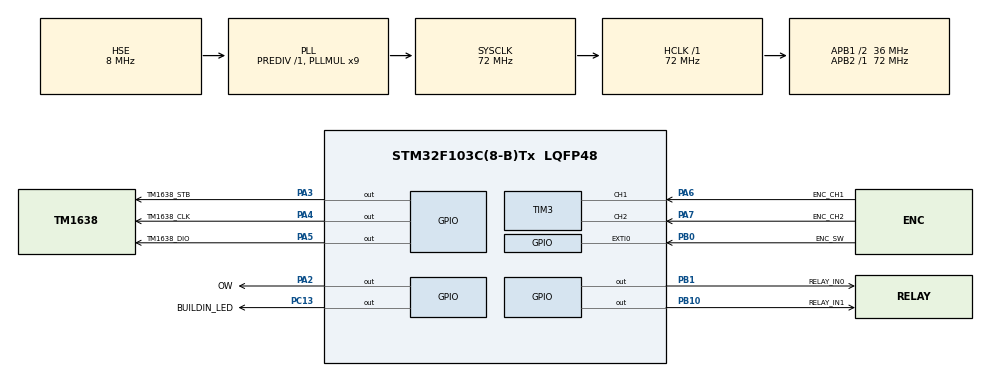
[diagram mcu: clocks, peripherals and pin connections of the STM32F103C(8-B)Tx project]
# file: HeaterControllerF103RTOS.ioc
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FREERTOS.Tasks01=runtime,24,512,start_runtime,Default,NULL,Dynamic,NULL,NULL
FREERTOS.configUSE_NEWLIB_REENTRANT=1
IWDG.Prescaler=IWDG_PRESCALER_256
Mcu.Family=STM32F1
Mcu.Name=STM32F103C(8-B)Tx
Mcu.Package=LQFP48
NVIC.EXTI0_IRQn=true\:5\:0\:false\:false\:true\:true\:true\:true\:true
NVIC.PriorityGroup=NVIC_PRIORITYGROUP_4
NVIC.TIM4_IRQn=true\:15\:0\:false\:false\:true\:false\:false\:true\:true
NVIC.TimeBase=TIM4_IRQn
NVIC.TimeBaseIP=TIM4
PA13.Mode=Serial_Wire
PA13.Signal=SYS_JTMS-SWDIO
PA14.Mode=Serial_Wire
PA14.Signal=SYS_JTCK-SWCLK
PA2.GPIO_Label=OW
PA2.GPIO_ModeDefaultOutputPP=GPIO_MODE_OUTPUT_OD
PA2.GPIO_PuPd=GPIO_NOPULL
PA2.PinState=GPIO_PIN_SET
PA2.Signal=GPIO_Output
PA3.GPIO_Label=TM1638_STB
PA3.Signal=GPIO_Output
PA4.GPIO_Label=TM1638_CLK
PA4.Signal=GPIO_Output
PA5.GPIO_Label=TM1638_DIO
PA5.Signal=GPIO_Output
PA6.GPIO_Label=ENC_CH1
PA6.GPIO_Mode=GPIO_MODE_INPUT
PA6.Signal=S_TIM3_CH1
PA7.GPIO_Label=ENC_CH2
PA7.Signal=S_TIM3_CH2
PB0.GPIO_Label=ENC_SW
PB0.GPIO_ModeDefaultEXTI=GPIO_MODE_IT_FALLING
PB0.GPIO_PuPd=GPIO_PULLUP
PB0.Signal=GPXTI0
PB1.GPIO_Label=RELAY_IN0
PB1.GPIO_ModeDefaultOutputPP=GPIO_MODE_OUTPUT_PP
PB1.GPIO_PuPd=GPIO_NOPULL
PB1.Signal=GPIO_Output
PB10.GPIO_Label=RELAY_IN1
PB10.GPIO_ModeDefaultOutputPP=GPIO_MODE_OUTPUT_PP
PB10.Signal=GPIO_Output
PC13-TAMPER-RTC.GPIO_Label=BUILDIN_LED
PC13-TAMPER-RTC.Signal=GPIO_Output
PD0-OSC_IN.Mode=HSE-External-Oscillator
PD0-OSC_IN.Signal=RCC_OSC_IN
PD1-OSC_OUT.Mode=HSE-External-Oscillator
PD1-OSC_OUT.Signal=RCC_OSC_OUT
ProjectManager.HeapSize=0x400
ProjectManager.StackSize=0x800
ProjectManager.TargetToolchain=STM32CubeIDE
RCC.AHBFreq_Value=72000000
RCC.APB1CLKDivider=RCC_HCLK_DIV2
RCC.APB1Freq_Value=36000000
RCC.APB1TimFreq_Value=72000000
RCC.APB2Freq_Value=72000000
RCC.APB2TimFreq_Value=72000000
RCC.HCLKFreq_Value=72000000
RCC.PLLMUL=RCC_PLL_MUL9
RCC.PLLSourceVirtual=RCC_PLLSOURCE_HSE
RCC.SYSCLKFreq_VALUE=72000000
RCC.SYSCLKSource=RCC_SYSCLKSOURCE_PLLCLK
RCC.USBFreq_Value=72000000
SH.S_TIM3_CH1.0=TIM3_CH1,Encoder_Interface
SH.S_TIM3_CH2.0=TIM3_CH2,Encoder_Interface
TIM1.Period=0xffff-1
TIM1.Prescaler=72-1
TIM3.EncoderMode=TIM_ENCODERMODE_TI12
TIM3.IC1Filter=10
VP_FREERTOS_VS_CMSIS_V2.Mode=CMSIS_V2
VP_IWDG_VS_IWDG.Mode=IWDG_Activate
VP_SYS_VS_tim4.Mode=TIM4
VP_TIM1_VS_ClockSourceINT.Mode=Internal
board=custom

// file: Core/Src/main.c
/* USER CODE BEGIN Header */
/**
  ******************************************************************************
  * @file           : main.c
  * @brief          : Main program body
  ******************************************************************************
  * @attention
  *
  * Copyright (c) 2024 STMicroelectronics.
  * All rights reserved.
  *
  * This software is licensed under terms that can be found in the LICENSE file
  * in the root directory of this software component.
  * If no LICENSE file comes with this software, it is provided AS-IS.
  *
  ******************************************************************************
  */
/* USER CODE END Header */
#include "main.h"
#include "cmsis_os.h"

/* USER CODE BEGIN Includes */
#include "controller.h"
#include "controller_devices.h"

/* USER CODE END Includes */

IWDG_HandleTypeDef hiwdg;

TIM_HandleTypeDef htim1;
TIM_HandleTypeDef htim3;

/* Definitions for runtime */
osThreadId_t runtimeHandle;
const osThreadAttr_t runtime_attributes = {
  .name = "runtime",
  .stack_size = 512 * 4,
  .priority = (osPriority_t) osPriorityNormal,
};

void SystemClock_Config(void);
static void MX_GPIO_Init(void);
static void MX_TIM1_Init(void);
static void MX_TIM3_Init(void);
static void MX_IWDG_Init(void);
void start_runtime(void *argument);

int main(void)
{

  /* MCU Configuration--------------------------------------------------------*/

  /* Reset of all peripherals, Initializes the Flash interface and the Systick. */
  HAL_Init();

  /* Configure the system clock */
  SystemClock_Config();

  /* Initialize all configured peripherals */
  MX_GPIO_Init();
  MX_TIM1_Init();
  MX_TIM3_Init();
  MX_IWDG_Init();
  /* USER CODE BEGIN 2 */
  HAL_TIM_Base_Start(&htim1);
  HAL_TIM_Encoder_Start(&htim3, TIM_CHANNEL_ALL);

  /* USER CODE END 2 */

  /* Init scheduler */
  osKernelInitialize();

  /* Create the thread(s) */
  /* creation of runtime */
  runtimeHandle = osThreadNew(start_runtime, NULL, &runtime_attributes);

  /* Start scheduler */
  osKernelStart();

  /* We should never get here as control is now taken by the scheduler */
  /* Infinite loop */
  while (1)
  {

  }
}

void SystemClock_Config(void)
{
  RCC_OscInitTypeDef RCC_OscInitStruct = {0};
  RCC_ClkInitTypeDef RCC_ClkInitStruct = {0};

  /** Initializes the RCC Oscillators according to the specified parameters
  * in the RCC_OscInitTypeDef structure.
  */
  RCC_OscInitStruct.OscillatorType = RCC_OSCILLATORTYPE_LSI|RCC_OSCILLATORTYPE_HSE;
  RCC_OscInitStruct.HSEState = RCC_HSE_ON;
  RCC_OscInitStruct.HSEPredivValue = RCC_HSE_PREDIV_DIV1;
  RCC_OscInitStruct.HSIState = RCC_HSI_ON;
  RCC_OscInitStruct.LSIState = RCC_LSI_ON;
  RCC_OscInitStruct.PLL.PLLState = RCC_PLL_ON;
  RCC_OscInitStruct.PLL.PLLSource = RCC_PLLSOURCE_HSE;
  RCC_OscInitStruct.PLL.PLLMUL = RCC_PLL_MUL9;
  if (HAL_RCC_OscConfig(&RCC_OscInitStruct) != HAL_OK)
  {
    Error_Handler();
  }

  /** Initializes the CPU, AHB and APB buses clocks
  */
  RCC_ClkInitStruct.ClockType = RCC_CLOCKTYPE_HCLK|RCC_CLOCKTYPE_SYSCLK
                              |RCC_CLOCKTYPE_PCLK1|RCC_CLOCKTYPE_PCLK2;
  RCC_ClkInitStruct.SYSCLKSource = RCC_SYSCLKSOURCE_PLLCLK;
  RCC_ClkInitStruct.AHBCLKDivider = RCC_SYSCLK_DIV1;
  RCC_ClkInitStruct.APB1CLKDivider = RCC_HCLK_DIV2;
  RCC_ClkInitStruct.APB2CLKDivider = RCC_HCLK_DIV1;

  if (HAL_RCC_ClockConfig(&RCC_ClkInitStruct, FLASH_LATENCY_2) != HAL_OK)
  {
    Error_Handler();
  }
}

static void MX_IWDG_Init(void)
{

  hiwdg.Instance = IWDG;
  hiwdg.Init.Prescaler = IWDG_PRESCALER_256;
  hiwdg.Init.Reload = 4095;
  if (HAL_IWDG_Init(&hiwdg) != HAL_OK)
  {
    Error_Handler();
  }

}

static void MX_TIM1_Init(void)
{

  TIM_ClockConfigTypeDef sClockSourceConfig = {0};
  TIM_MasterConfigTypeDef sMasterConfig = {0};

  htim1.Instance = TIM1;
  htim1.Init.Prescaler = 72-1;
  htim1.Init.CounterMode = TIM_COUNTERMODE_UP;
  htim1.Init.Period = 0xffff-1;
  htim1.Init.ClockDivision = TIM_CLOCKDIVISION_DIV1;
  htim1.Init.RepetitionCounter = 0;
  htim1.Init.AutoReloadPreload = TIM_AUTORELOAD_PRELOAD_DISABLE;
  if (HAL_TIM_Base_Init(&htim1) != HAL_OK)
  {
    Error_Handler();
  }
  sClockSourceConfig.ClockSource = TIM_CLOCKSOURCE_INTERNAL;
  if (HAL_TIM_ConfigClockSource(&htim1, &sClockSourceConfig) != HAL_OK)
  {
    Error_Handler();
  }
  sMasterConfig.MasterOutputTrigger = TIM_TRGO_RESET;
  sMasterConfig.MasterSlaveMode = TIM_MASTERSLAVEMODE_DISABLE;
  if (HAL_TIMEx_MasterConfigSynchronization(&htim1, &sMasterConfig) != HAL_OK)
  {
    Error_Handler();
  }

}

static void MX_TIM3_Init(void)
{

  TIM_Encoder_InitTypeDef sConfig = {0};
  TIM_MasterConfigTypeDef sMasterConfig = {0};

  htim3.Instance = TIM3;
  htim3.Init.Prescaler = 0;
  htim3.Init.CounterMode = TIM_COUNTERMODE_UP;
  htim3.Init.Period = 65535;
  htim3.Init.ClockDivision = TIM_CLOCKDIVISION_DIV1;
  htim3.Init.AutoReloadPreload = TIM_AUTORELOAD_PRELOAD_DISABLE;
  sConfig.EncoderMode = TIM_ENCODERMODE_TI12;
  sConfig.IC1Polarity = TIM_ICPOLARITY_RISING;
  sConfig.IC1Selection = TIM_ICSELECTION_DIRECTTI;
  sConfig.IC1Prescaler = TIM_ICPSC_DIV1;
  sConfig.IC1Filter = 10;
  sConfig.IC2Polarity = TIM_ICPOLARITY_RISING;
  sConfig.IC2Selection = TIM_ICSELECTION_DIRECTTI;
  sConfig.IC2Prescaler = TIM_ICPSC_DIV1;
  sConfig.IC2Filter = 0;
  if (HAL_TIM_Encoder_Init(&htim3, &sConfig) != HAL_OK)
  {
    Error_Handler();
  }
  sMasterConfig.MasterOutputTrigger = TIM_TRGO_RESET;
  sMasterConfig.MasterSlaveMode = TIM_MASTERSLAVEMODE_DISABLE;
  if (HAL_TIMEx_MasterConfigSynchronization(&htim3, &sMasterConfig) != HAL_OK)
  {
    Error_Handler();
  }

}

static void MX_GPIO_Init(void)
{
  GPIO_InitTypeDef GPIO_InitStruct = {0};

  /* GPIO Ports Clock Enable */
  __HAL_RCC_GPIOC_CLK_ENABLE();
  __HAL_RCC_GPIOD_CLK_ENABLE();
  __HAL_RCC_GPIOA_CLK_ENABLE();
  __HAL_RCC_GPIOB_CLK_ENABLE();

  /*Configure GPIO pin Output Level */
  HAL_GPIO_WritePin(BUILDIN_LED_GPIO_Port, BUILDIN_LED_Pin, GPIO_PIN_RESET);

  /*Configure GPIO pin Output Level */
  HAL_GPIO_WritePin(OW_GPIO_Port, OW_Pin, GPIO_PIN_SET);

  /*Configure GPIO pin Output Level */
  HAL_GPIO_WritePin(GPIOA, TM1638_STB_Pin|TM1638_CLK_Pin|TM1638_DIO_Pin, GPIO_PIN_RESET);

  /*Configure GPIO pin Output Level */
  HAL_GPIO_WritePin(GPIOB, RELAY_IN0_Pin|RELAY_IN1_Pin, GPIO_PIN_RESET);

  /*Configure GPIO pin : BUILDIN_LED_Pin */
  GPIO_InitStruct.Pin = BUILDIN_LED_Pin;
  GPIO_InitStruct.Mode = GPIO_MODE_OUTPUT_PP;
  GPIO_InitStruct.Pull = GPIO_NOPULL;
  GPIO_InitStruct.Speed = GPIO_SPEED_FREQ_LOW;
  HAL_GPIO_Init(BUILDIN_LED_GPIO_Port, &GPIO_InitStruct);

  /*Configure GPIO pin : OW_Pin */
  GPIO_InitStruct.Pin = OW_Pin;
  GPIO_InitStruct.Mode = GPIO_MODE_OUTPUT_OD;
  GPIO_InitStruct.Pull = GPIO_NOPULL;
  GPIO_InitStruct.Speed = GPIO_SPEED_FREQ_LOW;
  HAL_GPIO_Init(OW_GPIO_Port, &GPIO_InitStruct);

  /*Configure GPIO pins : TM1638_STB_Pin TM1638_CLK_Pin TM1638_DIO_Pin */
  GPIO_InitStruct.Pin = TM1638_STB_Pin|TM1638_CLK_Pin|TM1638_DIO_Pin;
  GPIO_InitStruct.Mode = GPIO_MODE_OUTPUT_PP;
  GPIO_InitStruct.Pull = GPIO_NOPULL;
  GPIO_InitStruct.Speed = GPIO_SPEED_FREQ_LOW;
  HAL_GPIO_Init(GPIOA, &GPIO_InitStruct);

  /*Configure GPIO pin : ENC_SW_Pin */
  GPIO_InitStruct.Pin = ENC_SW_Pin;
  GPIO_InitStruct.Mode = GPIO_MODE_IT_FALLING;
  GPIO_InitStruct.Pull = GPIO_PULLUP;
  HAL_GPIO_Init(ENC_SW_GPIO_Port, &GPIO_InitStruct);

  /*Configure GPIO pins : RELAY_IN0_Pin RELAY_IN1_Pin */
  GPIO_InitStruct.Pin = RELAY_IN0_Pin|RELAY_IN1_Pin;
  GPIO_InitStruct.Mode = GPIO_MODE_OUTPUT_PP;
  GPIO_InitStruct.Pull = GPIO_NOPULL;
  GPIO_InitStruct.Speed = GPIO_SPEED_FREQ_LOW;
  HAL_GPIO_Init(GPIOB, &GPIO_InitStruct);

  /* EXTI interrupt init*/
  HAL_NVIC_SetPriority(EXTI0_IRQn, 5, 0);
  HAL_NVIC_EnableIRQ(EXTI0_IRQn);

}

/* USER CODE BEGIN 4 */
void HAL_GPIO_EXTI_Callback(uint16_t GPIO_Pin)
{
	if(GPIO_Pin == ENC_SW_Pin)
	{
		encoder_set_sw_flag();
	}
}

/* USER CODE END 4 */

void start_runtime(void *argument)
{
  /* USER CODE BEGIN 5 */

	controller_t *controller;
	controller_init(&controller);

  for(;;)
  {
	  controller_run(controller);
	  HAL_IWDG_Refresh(&hiwdg);
    //runtime_controller_run(runtime_controller);
  }
  /* USER CODE END 5 */
}

void HAL_TIM_PeriodElapsedCallback(TIM_HandleTypeDef *htim)
{
  if (htim->Instance == TIM4) {
    HAL_IncTick();
  }
}

void Error_Handler(void)
{
  /* USER CODE BEGIN Error_Handler_Debug */
  /* User can add his own implementation to report the HAL error return state */
  __disable_irq();
  NVIC_SystemReset();
  while (1)
  {
  }
  /* USER CODE END Error_Handler_Debug */
}
